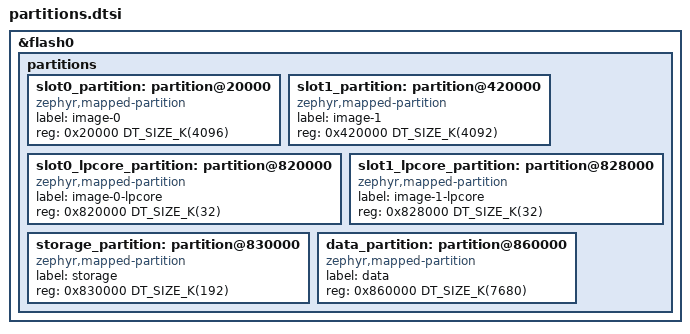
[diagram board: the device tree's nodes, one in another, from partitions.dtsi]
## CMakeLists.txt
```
# SPDX-License-Identifier: Apache-2.0
# Smartwatch firmware for the Waveshare ESP32-C6-Touch-LCD-1.69 (Zephyr port
# of the ESP-IDF firmware: the app/ and ui/ code is shared, compat/ maps the
# ESP-IDF and FreeRTOS calls it makes onto Zephyr).

cmake_minimum_required(VERSION 3.20.0)
find_package(Zephyr REQUIRED HINTS $ENV{ZEPHYR_BASE})
project(smartwatch)

file(GLOB WATCH_SRCS
  src/*.c src/hal/*.c src/app/*.c src/ui/*.c src/ui/faces/*.c src/port/*.c
  compat/*.c lib/cjson/*.c)


# The face-upload page, linked in like ESP-IDF's EMBED_FILES
list(APPEND WATCH_SRCS compat/faces_html.S)
set_source_files_properties(compat/faces_html.S PROPERTIES
  COMPILE_DEFINITIONS "FACES_HTML=\"${CMAKE_CURRENT_SOURCE_DIR}/web/faces.html\""
  OBJECT_DEPENDS ${CMAKE_CURRENT_SOURCE_DIR}/web/faces.html)

target_sources(app PRIVATE ${WATCH_SRCS})

# compat/ comes first so its esp_*.h and freertos/*.h win over hal_espressif's
target_include_directories(app BEFORE PRIVATE compat src lib/cjson)
# ui/theme.c reaches into LVGL's private theme header
target_include_directories(app PRIVATE ${ZEPHYR_LVGL_MODULE_DIR})
# malloc & co. on the kernel heap (compat/heap_wrap.c)
zephyr_ld_options(-Wl,--wrap=malloc -Wl,--wrap=free -Wl,--wrap=calloc
                  -Wl,--wrap=realloc -Wl,--wrap=aligned_alloc)

target_compile_options(app PRIVATE
  "SHELL:$<$<COMPILE_LANGUAGE:C>:-include ${CMAKE_CURRENT_SOURCE_DIR}/compat/watch_fs.h>"
  "SHELL:$<$<COMPILE_LANGUAGE:C>:-include ${CMAKE_CURRENT_SOURCE_DIR}/compat/lv_compat.h>"
  -Wno-unused-function -Wno-format-truncation -Wno-unused-variable)
target_compile_definitions(app PRIVATE WATCH_LOG_LEVEL=3 _GNU_SOURCE)
```

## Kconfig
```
mainmenu "Smartwatch"

menu "Smartwatch"

    config WATCH_WIFI_SSID
        string "Default Wi-Fi SSID (optional)"
        default ""
        help
            Fallback network for NTP time sync, used only until a network is
            connected from the watch's Wi-Fi tab (which is saved in NVS and
            takes priority).  Leave empty to set up Wi-Fi on the watch.

    config WATCH_WIFI_PASSWORD
        string "Default Wi-Fi password"
        default ""

    config WATCH_NTP_SERVER
        string "NTP server"
        default "pool.ntp.org"

    config WATCH_TIMEZONE
        string "Default timezone (POSIX TZ string)"
        default "UTC0"
        help
            Examples: "UTC0", "CET-1CEST,M3.5.0,M10.5.0/3",
            "EST5EDT,M3.2.0,M11.1.0", "IST-5:30", "JST-9".
            The RTC always stores UTC; this only affects what is displayed.
            Used until a timezone is picked on the watch (Settings → Time).

    config WATCH_TIME_SYNC_INTERVAL_H
        int "Hours between automatic time syncs"
        range 1 168
        default 12

    config WATCH_STEP_GOAL
        int "Daily step goal"
        default 8000

endmenu

source "Kconfig.zephyr"
```

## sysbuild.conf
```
# MCUboot for wireless updates: the new image goes to slot1, MCUboot swaps
# it in and swaps back unless the new firmware confirms itself.
SB_CONFIG_BOOTLOADER_MCUBOOT=y
SB_CONFIG_MCUBOOT_MODE_SWAP_USING_MOVE=y
```

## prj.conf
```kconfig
# Smartwatch for the Waveshare ESP32-C6-Touch-LCD-1.69 (Zephyr)

# ---- Display / LVGL ----
CONFIG_DISPLAY=y
CONFIG_LVGL=y
CONFIG_LV_Z_MEM_POOL_HEAP_LIB_C=y
# One 10 % draw buffer (13 KB).  Double buffering let LVGL render the next
# strip while the previous one went out over SPI, but cost another 13 KB plus
# a flush thread; a strip takes ~2 ms to send, so the gain was small.
CONFIG_LV_Z_DOUBLE_VDB=n
CONFIG_LV_Z_FLUSH_THREAD=n
CONFIG_LV_Z_VDB_SIZE=10
CONFIG_LV_DEF_REFR_PERIOD=16
CONFIG_LV_USE_LOG=n
CONFIG_LV_COLOR_DEPTH_16=y
CONFIG_LV_USE_THEME_DEFAULT=y
CONFIG_LV_THEME_DEFAULT_DARK=y
CONFIG_LV_USE_FLEX=y
CONFIG_LV_USE_GRID=y
CONFIG_LV_USE_OBSERVER=y
CONFIG_LV_USE_SNAPSHOT=y
CONFIG_LV_USE_ARC=y
CONFIG_LV_USE_BAR=y
CONFIG_LV_USE_BUTTON=y
CONFIG_LV_USE_BUTTONMATRIX=y
CONFIG_LV_USE_CANVAS=y
CONFIG_LV_USE_CHART=y
CONFIG_LV_USE_DROPDOWN=y
CONFIG_LV_USE_IMAGE=y
CONFIG_LV_USE_KEYBOARD=y
CONFIG_LV_USE_LABEL=y
CONFIG_LV_LABEL_LONG_TXT_HINT=y
CONFIG_LV_USE_LINE=y
CONFIG_LV_USE_ROLLER=y
CONFIG_LV_USE_SLIDER=y
CONFIG_LV_USE_SPINNER=y
CONFIG_LV_USE_SWITCH=y
CONFIG_LV_USE_TEXTAREA=y
CONFIG_LV_USE_TILEVIEW=y
CONFIG_LV_USE_FONT_PLACEHOLDER=y
CONFIG_LV_FONT_MONTSERRAT_14=y
CONFIG_LV_FONT_MONTSERRAT_16=y
CONFIG_LV_FONT_MONTSERRAT_20=y
CONFIG_LV_FONT_MONTSERRAT_24=y
CONFIG_LV_FONT_MONTSERRAT_36=y
CONFIG_LV_FONT_MONTSERRAT_48=y
CONFIG_LV_FONT_DEFAULT_MONTSERRAT_16=y

# ---- Board peripherals (touch, IMU, RTC and codec are driven by the app over I2C) ----
CONFIG_I2C=y
CONFIG_GPIO=y
CONFIG_ADC=y
CONFIG_PWM=y
CONFIG_LED=y
CONFIG_LED_PWM=y
CONFIG_HWINFO=y
CONFIG_REBOOT=y
CONFIG_INPUT=n
CONFIG_SENSOR=n
CONFIG_RTC=n

# ---- Storage: settings (NVS) and LittleFS at /data ----
CONFIG_FLASH=y
CONFIG_FLASH_MAP=y
CONFIG_NVS=y
CONFIG_SETTINGS=y
CONFIG_SETTINGS_NVS=y
CONFIG_SETTINGS_RUNTIME=y
CONFIG_FILE_SYSTEM=y
CONFIG_FILE_SYSTEM_LITTLEFS=y
CONFIG_FS_LITTLEFS_FMP_DEV=y
CONFIG_FS_LITTLEFS_CACHE_SIZE=512
CONFIG_FS_LITTLEFS_LOOKAHEAD_SIZE=64
CONFIG_FILE_SYSTEM_MAX_FILE_NAME=64

# ---- libc / time ----
CONFIG_PICOLIBC=y
CONFIG_SYS_HEAP_RUNTIME_STATS=y
CONFIG_REQUIRES_FLOAT_PRINTF=y
CONFIG_RING_BUFFER=y
CONFIG_EVENTS=y

# ---- kernel ----
CONFIG_MAIN_STACK_SIZE=3072
CONFIG_SYSTEM_WORKQUEUE_STACK_SIZE=2048
# One heap for the app, LVGL, Wi-Fi and Bluetooth (compat/heap_wrap.c)
CONFIG_HEAP_MEM_POOL_SIZE=184320
CONFIG_THREAD_NAME=y
CONFIG_TIMESLICING=y

# ---- console / shell ----
CONFIG_SHELL=y
CONFIG_SHELL_BACKEND_SERIAL=y
CONFIG_SHELL_STACK_SIZE=4096
CONFIG_SHELL_BACKEND_SERIAL_RX_RING_BUFFER_SIZE=512
CONFIG_SHELL_CMD_BUFF_SIZE=1024
CONFIG_LOG=y
CONFIG_LOG_DEFAULT_LEVEL=2
CONFIG_DYNAMIC_THREAD=y
CONFIG_DYNAMIC_THREAD_ALLOC=y
CONFIG_DYNAMIC_THREAD_PREFER_ALLOC=y
CONFIG_BOOT_BANNER=y
CONFIG_LOG_MODE_IMMEDIATE=y
CONFIG_FS_LOG_LEVEL_OFF=y
# printk straight to the console (not through the shell's log backend)
CONFIG_LOG_PRINTK=n
CONFIG_I2S=y
CONFIG_I2S_LOG_LEVEL_WRN=y

# Networking / Wi-Fi
CONFIG_NETWORKING=y
CONFIG_WIFI=y
CONFIG_WIFI_ESP32=y
CONFIG_NET_L2_WIFI_MGMT=y
CONFIG_NET_IPV4=y
CONFIG_NET_IPV6=n
CONFIG_NET_DHCPV4=y
CONFIG_NET_TCP=y
CONFIG_NET_UDP=y
CONFIG_NET_SOCKETS=y
CONFIG_DNS_RESOLVER=y
CONFIG_SNTP=y
CONFIG_NET_MGMT=y
CONFIG_NET_MGMT_EVENT=y
CONFIG_NET_MGMT_EVENT_INFO=y
CONFIG_NET_MGMT_EVENT_QUEUE_SIZE=16
CONFIG_NET_MGMT_EVENT_QUEUE_TIMEOUT=5000
CONFIG_NET_PKT_RX_COUNT=16
CONFIG_NET_PKT_TX_COUNT=16
CONFIG_NET_BUF_RX_COUNT=24
CONFIG_NET_BUF_DATA_SIZE=256
CONFIG_NET_BUF_TX_COUNT=24
CONFIG_NET_MAX_CONTEXTS=6
CONFIG_NET_MAX_CONN=4
CONFIG_NET_TX_STACK_SIZE=2048
CONFIG_NET_RX_STACK_SIZE=2048
CONFIG_WIFI_LOG_LEVEL_ERR=y
CONFIG_NET_LOG=y
CONFIG_ENTROPY_GENERATOR=y

# Wireless updates (MCUboot slots)
CONFIG_IMG_MANAGER=y
CONFIG_MCUBOOT_IMG_MANAGER=y
CONFIG_STREAM_FLASH=y
CONFIG_STREAM_FLASH_ERASE=y
CONFIG_FLASH_PAGE_LAYOUT=y
# Loopback interface, used by "watch http" to test the web server on the watch
CONFIG_NET_DRIVERS=y
CONFIG_NET_LOOPBACK=y
CONFIG_NET_IF_MAX_IPV4_COUNT=2

# Bluetooth LE: Gadgetbridge (Nordic UART), HID keyboard/mouse, media keys
CONFIG_BT=y
CONFIG_BT_PERIPHERAL=y
CONFIG_BT_SMP=y
CONFIG_BT_SMP_ALLOW_UNAUTH_OVERWRITE=y
CONFIG_BT_SETTINGS=y
CONFIG_BT_GATT_DYNAMIC_DB=y
CONFIG_BT_DEVICE_NAME="C6 Watch"
CONFIG_BT_DEVICE_NAME_DYNAMIC=y
CONFIG_BT_DEVICE_NAME_MAX=24
CONFIG_BT_DEVICE_APPEARANCE_DYNAMIC=y
CONFIG_BT_ID_MAX=2
CONFIG_BT_MAX_CONN=1
CONFIG_BT_MAX_PAIRED=6
CONFIG_BT_BAS=y
CONFIG_BT_L2CAP_TX_MTU=185
CONFIG_BT_BUF_ACL_RX_SIZE=189
CONFIG_BT_BUF_ACL_TX_SIZE=189
CONFIG_BT_LOG_LEVEL_WRN=y
CONFIG_ESP32_SW_COEXIST_ENABLE=y
# Fewer Wi-Fi driver buffers (allocated from the heap at start-up)
CONFIG_ESP32_WIFI_STATIC_RX_BUFFER_NUM=6
CONFIG_ESP32_WIFI_DYNAMIC_RX_BUFFER_NUM=16
CONFIG_ESP32_WIFI_DYNAMIC_TX_BUFFER_NUM=16
CONFIG_ESP32_WIFI_MGMT_SBUF_NUM=12
```

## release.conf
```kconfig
# Release build: ./build.sh -p release  (adds this file on top of prj.conf)
#
# Leaves out the UART shell and its test commands (src/port/shell_cmds.c),
# saving ~9 KB of RAM (stack, context, history and command buffers).
# Errors and warnings still go to the UART.
CONFIG_SHELL=n
CONFIG_INIT_STACKS=n
CONFIG_THREAD_ANALYZER=n
CONFIG_LOG_DEFAULT_LEVEL=2
# The RAM the shell used goes to the shared kernel heap (prj.conf: 180 KB)
CONFIG_HEAP_MEM_POOL_SIZE=196608
```

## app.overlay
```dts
/*
 * Smartwatch board tweaks:
 *  - the app talks to the touch controller, IMU and RTC itself over I2C and
 *    polls the buttons, so their Zephyr drivers are switched off;
 *  - flash layout in partitions.dtsi (shared with MCUboot).
 */
#include "partitions.dtsi"

/* ES8311 codec: I2S with MCLK on GPIO19 (pins in the board's i2s_default) */
&i2s {
	status = "okay";
};
```

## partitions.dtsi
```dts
/* Flash layout shared by the app and MCUboot (sysbuild/mcuboot.overlay):
 * two app slots for wireless updates (slot1 is one sector smaller, as
 * MCUboot's swap-move needs), settings, and a 7.5 MB LittleFS partition
 * mounted at /data. */
&flash0 {
	partitions {
		/delete-node/ partition@20000;
		/delete-node/ partition@7e0000;
		/delete-node/ partition@fa0000;
		/delete-node/ partition@fa8000;
		/delete-node/ partition@fb0000;

		slot0_partition: partition@20000 {
			compatible = "zephyr,mapped-partition";
			label = "image-0";
			reg = <0x20000 DT_SIZE_K(4096)>;
		};
		slot1_partition: partition@420000 {
			compatible = "zephyr,mapped-partition";
			label = "image-1";
			reg = <0x420000 DT_SIZE_K(4092)>;
		};
		slot0_lpcore_partition: partition@820000 {
			compatible = "zephyr,mapped-partition";
			label = "image-0-lpcore";
			reg = <0x820000 DT_SIZE_K(32)>;
		};
		slot1_lpcore_partition: partition@828000 {
			compatible = "zephyr,mapped-partition";
			label = "image-1-lpcore";
			reg = <0x828000 DT_SIZE_K(32)>;
		};
		storage_partition: partition@830000 {
			compatible = "zephyr,mapped-partition";
			label = "storage";
			reg = <0x830000 DT_SIZE_K(192)>;
		};
		data_partition: partition@860000 {
			compatible = "zephyr,mapped-partition";
			label = "data";
			reg = <0x860000 DT_SIZE_K(7680)>;
		};
	};
};
```

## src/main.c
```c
/**
 * @file main.c
 * @brief Smartwatch firmware for the Waveshare ESP32-C6-Touch-LCD-1.69.
 *
 * Boot order matters:
 *   1. power_hold()      — latch battery power before the user lets go of PWR
 *   2. NVS + settings
 *   3. I2C bus, then RTC (sets the system clock), display/LVGL, touch
 *   4. IMU, audio, battery ADC  (optional — the watch still runs without them)
 *   5. UI, then background services (activity, buttons, Wi-Fi manager)
 */

#include <stdlib.h>
#include <time.h>
#include "esp_log.h"
#include "nvs_flash.h"
#include "sdkconfig.h"

#include "hal/power.h"
#include "hal/button.h"
#include "pinout.h"
#include "hal/i2c_bus.h"
#include "hal/rtc.h"
#include "hal/display.h"
#include "hal/touch.h"
#include "hal/imu.h"
#include "hal/audio.h"
#include "hal/battery.h"
#include "hal/storage.h"
#include "app/recorder.h"
#include "app/settings.h"
#include "app/activity.h"
#include "app/wifi_mgr.h"
#include "app/ble_mgr.h"
#include "app/contacts.h"
#include "app/weather.h"
#include "app/calendar.h"
#include "app/ota_update.h"
#include "ui/ui_manager.h"
#include "lvgl_port.h"

static const char *TAG = "main";

void on_button(button_id_t id, button_event_t ev)
{
    const watch_settings_t *cfg = settings_get();
    bool pwr = id == BUTTON_PWR;
    switch (ev) {
    case BUTTON_CLICK:  ui_handle_button_action(pwr ? cfg->pwr_click  : cfg->boot_click, pwr);  break;
    case BUTTON_DOUBLE: ui_handle_button_action(pwr ? cfg->pwr_double : cfg->boot_double, pwr); break;
    case BUTTON_HOLD:   ui_handle_button_action(pwr ? cfg->pwr_long   : cfg->boot_long, pwr);   break;
    case BUTTON_LONG_HOLD:
        /* Whatever PWR is set to, a 5 s hold always reaches Restart / Power off */
        if (pwr && cfg->pwr_long != BTN_ACT_POWER_MENU) ui_handle_power_long_press();
        break;
    }
}

static void on_wrist_raise(void)
{
    ui_screen_wake();
}

static void init_nvs(void)
{
    esp_err_t err = nvs_flash_init();
    if (err == ESP_ERR_NVS_NO_FREE_PAGES || err == ESP_ERR_NVS_NEW_VERSION_FOUND) {
        ESP_ERROR_CHECK(nvs_flash_erase());
        err = nvs_flash_init();
    }
    ESP_ERROR_CHECK(err);
}

void app_main(void)
{
    power_hold();

    init_nvs();
    watch_settings_load();
    watch_settings_t *cfg = settings_get();

    settings_apply_timezone();

    ESP_ERROR_CHECK(i2c_bus_init());
    if (rtc_init() != ESP_OK) ESP_LOGE(TAG, "RTC unavailable");

    ESP_ERROR_CHECK(display_init(settings_get()->fps30));
    ESP_ERROR_CHECK(lvgl_port_init());
    if (touch_init() != ESP_OK) ESP_LOGE(TAG, "Touch unavailable");

    bool imu_ok = imu_init() == ESP_OK;
    if (audio_init() == ESP_OK) {
        audio_set_volume(cfg->volume);
    } else {
        ESP_LOGE(TAG, "Audio unavailable");
    }
    if (battery_init() != ESP_OK) ESP_LOGE(TAG, "Battery ADC unavailable");
    if (storage_init() == ESP_OK) {
        recorder_init();
    } else {
        ESP_LOGE(TAG, "Storage unavailable — no voice recordings");
    }

    contacts_init();                     // Phone app: favourites + recent calls
    weather_init();                      // last weather and calendar from the phone
    calendar_init();

    ESP_ERROR_CHECK(ui_init());

    if (imu_ok) {
        activity_set_raise_cb(on_wrist_raise);
        activity_start();
    } else {
        ESP_LOGE(TAG, "IMU unavailable — no steps or raise-to-wake");
    }
    button_set_double(BUTTON_PWR, settings_get()->pwr_double != BTN_ACT_NONE);
    button_set_double(BUTTON_BOOT, settings_get()->boot_double != BTN_ACT_NONE);
    ESP_ERROR_CHECK(button_start(BUTTON_PWR, PIN_BTN_PWR, on_button));
    if (button_start(BUTTON_BOOT, PIN_BTN_BOOT, on_button) != ESP_OK) ESP_LOGE(TAG, "BOOT button unavailable");
    if (wifi_mgr_start() != ESP_OK) ESP_LOGE(TAG, "Wi-Fi unavailable");
    if (ble_mgr_start() != ESP_OK) ESP_LOGE(TAG, "Bluetooth unavailable");

    extern size_t watch_heap_free(void);
    ESP_LOGI(TAG, "Smartwatch running, heap free %u", (unsigned)watch_heap_free());
    ota_confirm_running();               // a fresh update made it this far: keep it
}

/* Zephyr entry point: run the same start-up as ESP-IDF's app_main. */
#include "freertos/FreeRTOS.h"
#include "freertos/task.h"

/* Start-up runs on a heap stack that is given back afterwards, so the
 * Zephyr main thread itself only needs a small static stack. */
static void app_main_task(void *arg)
{
    app_main();
    vTaskDelete(NULL);
}

int main(void)
{
    if (xTaskCreate(app_main_task, "app_main", 8192, NULL, 14, NULL) != pdPASS) app_main();
    return 0;
}
```

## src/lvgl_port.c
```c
/**
 * @file lvgl_port.c
 * @brief LVGL tick source and handler task.
 */

#include "lvgl_port.h"

#include "esp_log.h"
#include "esp_timer.h"
#include "freertos/task.h"
#include "lvgl.h"

static const char *TAG = "lvgl_port";

#define LVGL_TASK_STACK      (8 * 1024)
#define LVGL_TASK_PRIO       4
#define LVGL_TASK_MIN_MS     5
#define LVGL_TASK_MAX_MS     50

SemaphoreHandle_t g_lvgl_mutex = NULL;

static uint32_t tick_get_cb(void)
{
    return (uint32_t)(esp_timer_get_time() / 1000);
}

static void lvgl_task(void *arg)
{
    for (;;) {
        lvgl_lock();
        uint32_t next_ms = lv_timer_handler();
        lvgl_unlock();

        if (next_ms < LVGL_TASK_MIN_MS) next_ms = LVGL_TASK_MIN_MS;
        if (next_ms > LVGL_TASK_MAX_MS) next_ms = LVGL_TASK_MAX_MS;
        vTaskDelay(pdMS_TO_TICKS(next_ms));
    }
}

esp_err_t lvgl_port_init(void)
{
    g_lvgl_mutex = xSemaphoreCreateRecursiveMutex();
    if (!g_lvgl_mutex) return ESP_ERR_NO_MEM;

    lv_tick_set_cb(tick_get_cb);

    if (xTaskCreate(lvgl_task, "lvgl", LVGL_TASK_STACK, NULL,
                    LVGL_TASK_PRIO, NULL) != pdPASS) {
        ESP_LOGE(TAG, "Failed to create LVGL task");
        return ESP_ERR_NO_MEM;
    }
    return ESP_OK;
}
```

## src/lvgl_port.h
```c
#pragma once
/**
 * @file lvgl_port.h
 * @brief LVGL tick source, handler task and thread-safety helpers.
 *
 * All tasks that create or modify LVGL objects MUST wrap their calls with
 * lvgl_lock() / lvgl_unlock().  The LVGL handler task already holds the
 * lock while calling lv_timer_handler(), so LVGL callbacks (events, lv_timer)
 * must NOT take it again — although the mutex is recursive, so doing so is
 * harmless.
 */

#include "freertos/FreeRTOS.h"
#include "freertos/semphr.h"
#include "esp_err.h"

/** Recursive mutex protecting all LVGL API calls. Created by lvgl_port_init(). */
extern SemaphoreHandle_t g_lvgl_mutex;

/**
 * @brief Install the LVGL tick source and start the LVGL handler task.
 *        Call after display_init() (which calls lv_init()).
 */
esp_err_t lvgl_port_init(void);

/* ui_init() holds the lock for about 0.5 s while it builds every screen,
 * so the LVGL task waits that long at boot.  At 500 ms this left a few ms of
 * margin and small UI additions caused a boot loop. */
#define LVGL_LOCK_TIMEOUT_MS  3000

/** Wait up to LVGL_LOCK_TIMEOUT_MS for the LVGL lock; assert on timeout. */
static inline void lvgl_lock(void)
{
    if (xSemaphoreTakeRecursive(g_lvgl_mutex, pdMS_TO_TICKS(LVGL_LOCK_TIMEOUT_MS)) != pdTRUE) {
        // Deadlock guard – should never happen in normal operation
        configASSERT(0);
    }
}

static inline void lvgl_unlock(void)
{
    xSemaphoreGiveRecursive(g_lvgl_mutex);
}
```

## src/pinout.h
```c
#pragma once

#include "driver/gpio.h"

// ─── Display & touch ────────────────────────────────────────────────────────
// ST7789V2 (SPI) + CST816T (I2C)
#define PIN_LCD_SCLK       GPIO_NUM_1
#define PIN_LCD_MOSI       GPIO_NUM_2
#define PIN_LCD_DC         GPIO_NUM_3
#define PIN_LCD_RST        GPIO_NUM_4
#define PIN_LCD_CS         GPIO_NUM_5
#define PIN_LCD_BL         GPIO_NUM_6
#define PIN_TP_INT         GPIO_NUM_11   // CST816T interrupt (active-low)
#define PIN_TP_RST         GPIO_NUM_NC   // Tied to LCD_RST (GPIO4) on the PCB

// ─── Shared I2C bus ─────────────────────────────────────────────────────────
// Shared by: CST816T (touch), PCF85063 (RTC), QMI8658 (IMU), ES8311 (codec)
#define PIN_I2C_SCL        GPIO_NUM_7
#define PIN_I2C_SDA        GPIO_NUM_8
#define I2C_BUS_PORT       I2C_NUM_0
#define I2C_BUS_SPEED_HZ   400000       // 400 kHz Fast-mode

// I2C device addresses
#define I2C_ADDR_CST816T   0x15
#define I2C_ADDR_PCF85063  0x51
#define I2C_ADDR_QMI8658   0x6B
#define I2C_ADDR_ES8311    0x18

// ─── Interrupt / wake pins ──────────────────────────────────────────────────
#define PIN_RTC_INT        GPIO_NUM_10   // PCF85063 alarm interrupt
// NOTE: GPIO9 = BOOT button AND QMI8658 INT1 — use IMU INT2 or polling
#define PIN_IMU_INT2       GPIO_NUM_NC   // Not connected on this board revision

// ─── Buttons ────────────────────────────────────────────────────────────────
#define PIN_BTN_BOOT       GPIO_NUM_9
#define PIN_BTN_PWR        GPIO_NUM_18   // Supports single/double/long-press (active-low)

// ─── Power / battery ────────────────────────────────────────────────────────
// Drive BAT_EN high early in boot to latch battery power on; otherwise the
// board turns off on battery as soon as PWR is released. Drive low to power off.
#define PIN_BAT_EN         GPIO_NUM_15
#define PIN_BAT_ADC        GPIO_NUM_0    // ADC1_CH0, battery via 1/3 divider (V = Vadc * 3)

// ─── Audio ──────────────────────────────────────────────────────────────────
// ES8311 codec (I2S) + NS4150B Class-D amp
// NS4150B CTRL is pulled up on the PCB (no GPIO) — amp is always enabled.
#define PIN_CODEC_MCLK     GPIO_NUM_19
#define PIN_CODEC_BCLK     GPIO_NUM_20
#define PIN_CODEC_ASDOUT   GPIO_NUM_21   // ADC out (mic → ESP)
#define PIN_CODEC_LRCK     GPIO_NUM_22
#define PIN_CODEC_DSDIN    GPIO_NUM_23   // DAC in  (ESP → speaker)

// ─── Display geometry ───────────────────────────────────────────────────────
#define LCD_H_RES          240
#define LCD_V_RES          280

// ─── Backlight LEDC ─────────────────────────────────────────────────────────
#define LEDC_BL_TIMER      LEDC_TIMER_0
#define LEDC_BL_MODE       LEDC_LOW_SPEED_MODE
#define LEDC_BL_CHANNEL    LEDC_CHANNEL_0
#define LEDC_BL_DUTY_RES   LEDC_TIMER_10_BIT   // 10-bit → 0–1023
#define LEDC_BL_FREQ_HZ    5000
```
